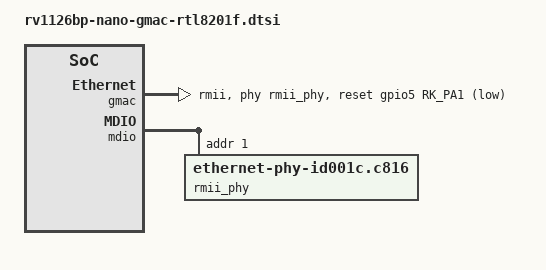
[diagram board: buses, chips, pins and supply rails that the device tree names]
// SPDX-License-Identifier: (GPL-2.0+ OR MIT)
/*
 * Copyright (c) 2025 Guangzhou EASY EAI Technology Co., Ltd.
 */

&gmac {
	phy-mode = "rmii";
	clock_in_out = "output";

	snps,reset-gpio = <&gpio5 RK_PA1 GPIO_ACTIVE_LOW>;
	snps,reset-active-low;
	/* Reset time is 20ms, 100ms for rtl8211f */
	snps,reset-delays-us = <0 20000 100000>;

	//assigned-clocks = <&cru CLK_MAC_OUT2IO>;
	//assigned-clock-rates = <25000000>;

	pinctrl-names = "default";
	pinctrl-0 = <&ethm1_miim_pins
		     &ethm1_tx_bus2_pins
		     &ethm1_rx_bus2_pins
		     // &ethm1_rgmii_clk_pins TXCLK RXCLK for rgmii
		     // &ethm1_rgmii_bus_pins R2 R3 TX T3 for rgmii
		     &ethm1_mclk_pins>;

	phy-handle = <&rmii_phy>;
	status = "okay";
};

&mdio {
	rmii_phy: phy@1 {
		compatible = "ethernet-phy-id001c.c816";
		reg = <0x1>;
		//clocks = <&cru CLK_MAC_OUT2IO>;
	};
};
